AUTOSAR XML (schema 00050)
package /ComponentTypes
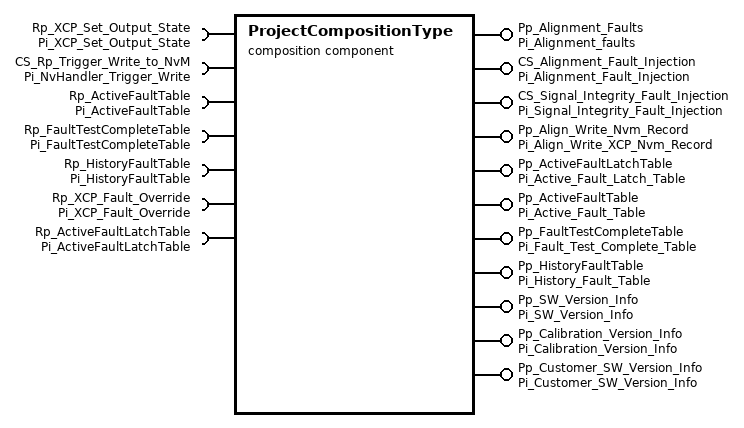
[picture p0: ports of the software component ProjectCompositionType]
  composition sw component type ProjectCompositionType
    provide port Pp_Alignment_Faults: nonqueued-sender-com-spec{data-element=De_Alignment_Faults, init-value=constant-reference=C_Alignment_faults}, provided-interface=Pi_Alignment_faults
    provide port CS_Alignment_Fault_Injection: server-com-spec{operation=read, queue-length=1}, provided-interface=Pi_Alignment_Fault_Injection
    provide port CS_Signal_Integrity_Fault_Injection: server-com-spec{operation=Read, queue-length=1}, provided-interface=Pi_Signal_Integrity_Fault_Injection
    require port Rp_XCP_Set_Output_State: nonqueued-receiver-com-spec{data-element=De_XCP_Set_Output, filter=data-filter-type=ALWAYS, init-value=constant-reference=C_XCP_Output_State}, required-interface=Pi_XCP_Set_Output_State
    require port CS_Rp_Trigger_Write_to_NvM: client-com-spec=NvHandler_Trigger_Write_To_NVM, required-interface=Pi_NvHandler_Trigger_Write
    provide port Pp_Align_Write_Nvm_Record: nonqueued-sender-com-spec{data-element=Alignment_Record, init-value=fields=[AACurrentAzimuth:0, AACurrentElevation:0, AACurrentRoll:0, 0, 0, 0, 0, ElevationUpdates:0, AzimuthUpdates:0, RollUpdates:0, 0, 0, HostSpeedCompensationFactor:0, 0, 0, AlignmentModeOut:0]}, provided-interface=Pi_Align_Write_XCP_Nvm_Record
    4 x require port:
      Rp_ActiveFaultTable: nonqueued-receiver-com-spec{data-element=De_ActiveFaultTable, filter=data-filter-type=ALWAYS}, required-interface=Pi_ActiveFaultTable
      Rp_FaultTestCompleteTable: nonqueued-receiver-com-spec{data-element=De_FaultTestCompleteTable, filter=data-filter-type=ALWAYS}, required-interface=Pi_FaultTestCompleteTable
      Rp_HistoryFaultTable: nonqueued-receiver-com-spec{data-element=De_HistoryFaultTable, filter=data-filter-type=ALWAYS, init-value=constant-reference=C_Fault_T}, required-interface=Pi_HistoryFaultTable
      Rp_XCP_Fault_Override: nonqueued-receiver-com-spec{data-element=De_XCP_Fault_Override, filter=data-filter-type=ALWAYS, init-value=constant-reference=C_XCP_Fault_Override}, required-interface=Pi_XCP_Fault_Override
    4 x provide port:
      Pp_ActiveFaultLatchTable: nonqueued-sender-com-spec{data-element=De_ActiveFaultLatchTable, init-value=constant-reference=C_Fault_T}, provided-interface=Pi_Active_Fault_Latch_Table
      Pp_ActiveFaultTable: nonqueued-sender-com-spec{data-element=De_ActiveFaultTable, init-value=constant-reference=C_Fault_T}, provided-interface=Pi_Active_Fault_Table
      Pp_FaultTestCompleteTable: nonqueued-sender-com-spec{data-element=De_FaultTestCompleteTable, init-value=constant-reference=C_Fault_T}, provided-interface=Pi_Fault_Test_Complete_Table
      Pp_HistoryFaultTable: nonqueued-sender-com-spec{data-element=De_HistoryFaultTable, init-value=constant-reference=C_Fault_T}, provided-interface=Pi_History_Fault_Table
    require port Rp_ActiveFaultLatchTable: nonqueued-receiver-com-spec{data-element=De_ActiveFaultLatchTable, filter=data-filter-type=ALWAYS, init-value=constant-reference=C_Fault_T}, required-interface=Pi_ActiveFaultLatchTable
    provide port Pp_SW_Version_Info: nonqueued-sender-com-spec{data-element=De_SW_Version_Info, init-value=fields=[SwReleaseRevision:0, SwMajorRevision:0, SwMinorRevision:0, SwFieldRevision:0, DbcMajorRevision:0, DbcMinorRevision:0, FBLMajorRevision:0, FBLMinorRevision:0, FBLPromoteRevision:0, BMMajorRevision:0, BMMinorRevision:0, BMFieldRevision:0, ASRMajorRevision:0, ASRMinorRevision:0, ASRfieldRevision:0]}, provided-interface=Pi_SW_Version_Info
    provide port Pp_Calibration_Version_Info: nonqueued-sender-com-spec{data-element=De_Calibration_Version_Info, init-value=fields=[SMC_MajorVersion:0, SMC_PlatformRevision:0, SMC_Compatablity:0, USC_MajorVersion:0, USC_PlatformRevision:0, USC_Compatablity:0, Julian_Year:0, Julian_Date:0]}, provided-interface=Pi_Calibration_Version_Info
    provide port Pp_Customer_SW_Version_Info: nonqueued-sender-com-spec{data-element=De_Customer_SW_Version_Info, init-value=fields=[{short-label=Customer_SW_Version, fields=[Major_Version:0, Minor_Version:0, Patch_Version:0]}, {short-label=Customer_BL_Version, fields=[Major_Version:0, Minor_Version:0, Patch_Version:0]}, {short-label=Customer_BM_Version, fields=[Major_Version:0, Minor_Version:0, Patch_Version:0]}]}, provided-interface=Pi_Customer_SW_Version_Info
    7 x component:
      SWC_PLT_Radar_Alignment_Handler: type=SWC_PLT_Radar_Alignment_Handler
      SWC_Appl_Project: type=SWC_Appl_Project
      SWC_PRJ_Appl_FaultMgr: type=SWC_PRJ_Appl_FaultMgr
      SWC_PRJ_Appl_Power_Manager: type=SWC_PRJ_Appl_Power_Manager
      SWC_CMP_PRJ_UDSHandler: type=SWC_CMP_PRJ_UDSHandler
      SWC_PRJ_Appl_SensorPosition: type=SWC_PRJ_Appl_SensorPosition
      SWC_PRJ_Appl_Security_Manager: type=SWC_PRJ_Appl_Security_Manager
    delegate SWC_PLT_Radar_Alignment_Handler.Pp_Alignment_Faults <-> outer port Pp_Alignment_Faults
    delegate SWC_PLT_Radar_Alignment_Handler.CS_Alignment_Fault_Injection <-> outer port CS_Alignment_Fault_Injection
    delegate SWC_Appl_Project.CS_Signal_Integrity_Fault_Injection <-> outer port CS_Signal_Integrity_Fault_Injection
    delegate SWC_Appl_Project.Rp_XCP_Set_Output_State <-> outer port Rp_XCP_Set_Output_State
    delegate SWC_PLT_Radar_Alignment_Handler.CS_Rp_Trigger_Write_to_NvM <-> outer port CS_Rp_Trigger_Write_to_NvM
    delegate SWC_PLT_Radar_Alignment_Handler.Pp_Align_Write_Nvm_Record <-> outer port Pp_Align_Write_Nvm_Record
    delegate SWC_PRJ_Appl_FaultMgr.Rp_ActiveFaultTable <-> outer port Rp_ActiveFaultTable
    delegate SWC_PRJ_Appl_FaultMgr.Rp_FaultTestCompleteTable <-> outer port Rp_FaultTestCompleteTable
    delegate SWC_PRJ_Appl_FaultMgr.Rp_HistoryFaultTable <-> outer port Rp_HistoryFaultTable
    delegate SWC_PRJ_Appl_FaultMgr.Pp_ActiveFaultLatchTable <-> outer port Pp_ActiveFaultLatchTable
    delegate SWC_PRJ_Appl_FaultMgr.Pp_ActiveFaultTable <-> outer port Pp_ActiveFaultTable
    delegate SWC_PRJ_Appl_FaultMgr.Pp_FaultTestCompleteTable <-> outer port Pp_FaultTestCompleteTable
    delegate SWC_PRJ_Appl_FaultMgr.Pp_HistoryFaultTable <-> outer port Pp_HistoryFaultTable
    delegate SWC_PRJ_Appl_FaultMgr.Rp_ActiveFaultLatchTable <-> outer port Rp_ActiveFaultLatchTable
    delegate SWC_CMP_PRJ_UDSHandler.Pp_SW_Version_Info <-> outer port Pp_SW_Version_Info
    delegate SWC_CMP_PRJ_UDSHandler.Pp_Calibration_Version_Info <-> outer port Pp_Calibration_Version_Info
    delegate SWC_CMP_PRJ_UDSHandler.Pp_Customer_SW_Version_Info <-> outer port Pp_Customer_SW_Version_Info
    delegate SWC_PRJ_Appl_FaultMgr.Rp_XCP_Fault_Override <-> outer port Rp_XCP_Fault_Override
